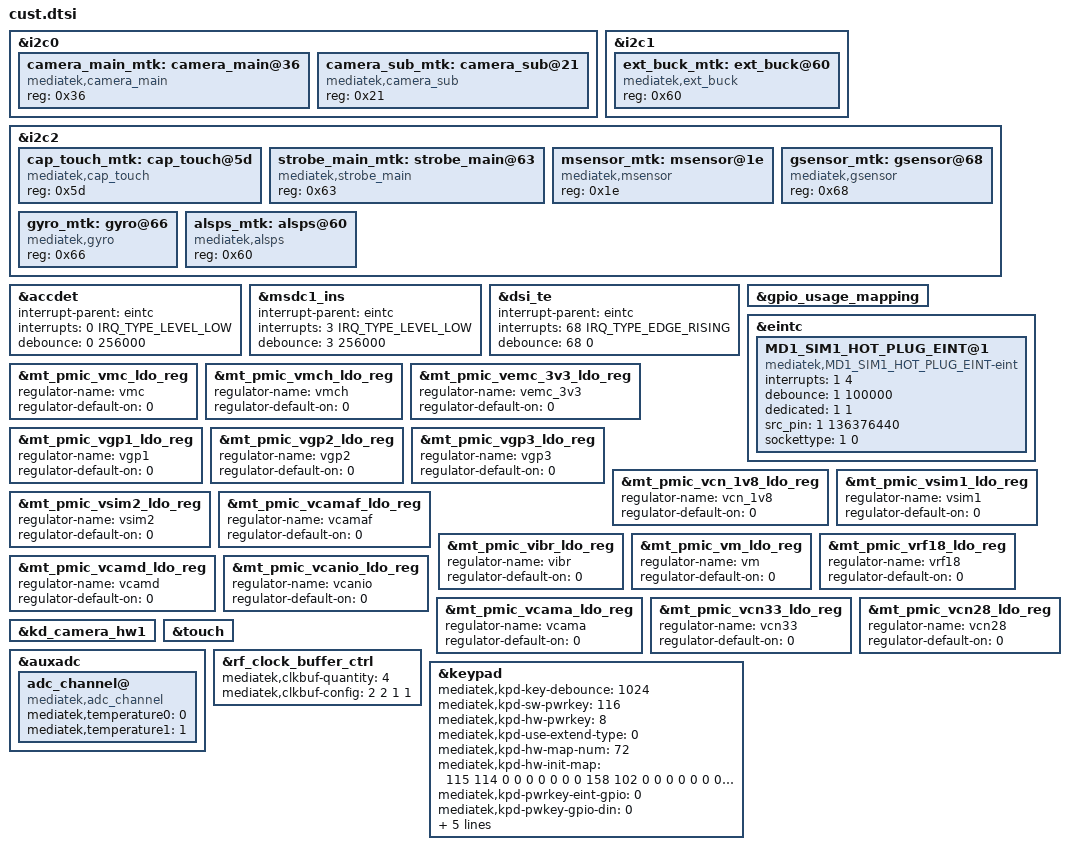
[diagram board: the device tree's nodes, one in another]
/*
 * Generated by MTK SP Drv_CodeGen Version 03.13.6  for MT6580. Copyright MediaTek Inc. (C) 2013.
 * Wed Sep 23 15:43:50 2020
 * Do Not Modify the File.
 */

/*************************
 * I2C DTSI File
*************************/

&i2c0 {
	#address-cells = <1>;
	#size-cells = <0>;
	camera_main_mtk:camera_main@36 {
		compatible = "mediatek,camera_main";
		reg = <0x36>;
		status = "okay";
	};
	camera_sub_mtk:camera_sub@21 {
		compatible = "mediatek,camera_sub";
		reg = <0x21>;
		status = "okay";
	};
};

&i2c1 {
	#address-cells = <1>;
	#size-cells = <0>;
	ext_buck_mtk:ext_buck@60 {
		compatible = "mediatek,ext_buck";
		reg = <0x60>;
		status = "okay";
	};
};

&i2c2 {
	#address-cells = <1>;
	#size-cells = <0>;
	cap_touch_mtk:cap_touch@5d {
		compatible = "mediatek,cap_touch";
		reg = <0x5d>;
		status = "okay";
	};
	strobe_main_mtk:strobe_main@63 {
		compatible = "mediatek,strobe_main";
		reg = <0x63>;
		status = "okay";
	};
	msensor_mtk:msensor@1e {
		compatible = "mediatek,msensor";
		reg = <0x1e>;
		status = "okay";
	};
	gsensor_mtk:gsensor@68 {
		compatible = "mediatek,gsensor";
		reg = <0x68>;
		status = "okay";
	};
	gyro_mtk:gyro@66 {
		compatible = "mediatek,gyro";
		reg = <0x66>;
		status = "okay";
	};
	alsps_mtk:alsps@60 {
		compatible = "mediatek,alsps";
		reg = <0x60>;
		status = "okay";
	};
};



#include <dt-bindings/interrupt-controller/irq.h>
#include <dt-bindings/interrupt-controller/arm-gic.h>

/*************************
 * EINT DTSI File
*************************/

&accdet {
	interrupt-parent = <&eintc>;
	interrupts = <0 IRQ_TYPE_LEVEL_LOW>;
	debounce = <0 256000>;
	status = "okay";
};
&msdc1_ins {
	interrupt-parent = <&eintc>;
	interrupts = <3 IRQ_TYPE_LEVEL_LOW>;
	debounce = <3 256000>;
	status = "okay";
};
&dsi_te {
	interrupt-parent = <&eintc>;
	interrupts = <68 IRQ_TYPE_EDGE_RISING>;
	debounce = <68 0>;
	status = "okay";
};


/********************
 * GPIO USAGE MAPPING DTSI File
****************/

&gpio_usage_mapping {
};


&eintc {
	MD1_SIM1_HOT_PLUG_EINT@1 {
		compatible = "mediatek,MD1_SIM1_HOT_PLUG_EINT-eint";
		interrupts = <1 4>;
		debounce = <1 100000>;
		dedicated = <1 1>;
		src_pin = <1 136376440>;
		sockettype=<1 0>;
		status = "okay";
	};
};


/*************************
 * PMIC DTSI File
*************************/

&mt_pmic_vmc_ldo_reg {
	regulator-name = "vmc";
	regulator-default-on = <0>; /* 0:skip, 1: off, 2:on */
	status = "okay";
};
&mt_pmic_vmch_ldo_reg {
	regulator-name = "vmch";
	regulator-default-on = <0>; /* 0:skip, 1: off, 2:on */
	status = "okay";
};
&mt_pmic_vemc_3v3_ldo_reg {
	regulator-name = "vemc_3v3";
	regulator-default-on = <0>; /* 0:skip, 1: off, 2:on */
	status = "okay";
};
&mt_pmic_vgp1_ldo_reg {
	regulator-name = "vgp1";
	regulator-default-on = <0>; /* 0:skip, 1: off, 2:on */
	status = "okay";
};
&mt_pmic_vgp2_ldo_reg {
	regulator-name = "vgp2";
	regulator-default-on = <0>; /* 0:skip, 1: off, 2:on */
	status = "okay";
};
&mt_pmic_vgp3_ldo_reg {
	regulator-name = "vgp3";
	regulator-default-on = <0>; /* 0:skip, 1: off, 2:on */
	status = "okay";
};
&mt_pmic_vcn_1v8_ldo_reg {
	regulator-name = "vcn_1v8";
	regulator-default-on = <0>; /* 0:skip, 1: off, 2:on */
	status = "okay";
};
&mt_pmic_vsim1_ldo_reg {
	regulator-name = "vsim1";
	regulator-default-on = <0>; /* 0:skip, 1: off, 2:on */
	status = "okay";
};
&mt_pmic_vsim2_ldo_reg {
	regulator-name = "vsim2";
	regulator-default-on = <0>; /* 0:skip, 1: off, 2:on */
	status = "okay";
};
&mt_pmic_vcamaf_ldo_reg {
	regulator-name = "vcamaf";
	regulator-default-on = <0>; /* 0:skip, 1: off, 2:on */
	status = "okay";
};
&mt_pmic_vibr_ldo_reg {
	regulator-name = "vibr";
	regulator-default-on = <0>; /* 0:skip, 1: off, 2:on */
	status = "okay";
};
&mt_pmic_vm_ldo_reg {
	regulator-name = "vm";
	regulator-default-on = <0>; /* 0:skip, 1: off, 2:on */
	status = "okay";
};
&mt_pmic_vrf18_ldo_reg {
	regulator-name = "vrf18";
	regulator-default-on = <0>; /* 0:skip, 1: off, 2:on */
	status = "okay";
};
&mt_pmic_vcamd_ldo_reg {
	regulator-name = "vcamd";
	regulator-default-on = <0>; /* 0:skip, 1: off, 2:on */
	status = "okay";
};
&mt_pmic_vcanio_ldo_reg {
	regulator-name = "vcanio";
	regulator-default-on = <0>; /* 0:skip, 1: off, 2:on */
	status = "okay";
};
&mt_pmic_vcama_ldo_reg {
	regulator-name = "vcama";
	regulator-default-on = <0>; /* 0:skip, 1: off, 2:on */
	status = "okay";
};
&mt_pmic_vcn33_ldo_reg {
	regulator-name = "vcn33";
	regulator-default-on = <0>; /* 0:skip, 1: off, 2:on */
	status = "okay";
};
&mt_pmic_vcn28_ldo_reg {
	regulator-name = "vcn28";
	regulator-default-on = <0>; /* 0:skip, 1: off, 2:on */
	status = "okay";
};

&kd_camera_hw1 {
	status = "okay";
};

&touch {
	status = "okay";
};


/********************************************
 *ADC DTSI File
********************************************/

&auxadc {
	adc_channel@ {
		compatible = "mediatek,adc_channel";
		mediatek,temperature0 = <0>;
		mediatek,temperature1 = <1>;
		status = "okay";
	};
};


/**********************************************
 *CLK_BUF DTSI File
********************************************/

&rf_clock_buffer_ctrl {
	mediatek,clkbuf-quantity = <4>;
	mediatek,clkbuf-config = <2 2 1 1>;
	status = "okay";
};


/**********************************************
 *Keypad DTSI File
********************************************/

&keypad{
	mediatek,kpd-key-debounce = <1024>;
	mediatek,kpd-sw-pwrkey = <116>;
	mediatek,kpd-hw-pwrkey = <8>;
	mediatek,kpd-use-extend-type = <0>;
	/*HW Keycode [0~71] -> Linux Keycode*/
	mediatek,kpd-hw-map-num = <72>;
	mediatek,kpd-hw-init-map = <115 114 0 0 0 0 0 0 0 158 
				102 0 0 0 0 0 0 0 0 
				0 0 0 0 0 0 0 0 0 
				0 0 0 0 0 0 0 0 0 
				0 0 0 0 0 0 0 0 0 
				0 0 0 0 0 0 0 0 0 
				0 0 0 0 0 0 0 0 0 
				0 0 0 0 0 0 0 0 >;
	mediatek,kpd-pwrkey-eint-gpio = <0>;
	mediatek,kpd-pwkey-gpio-din  = <0>;
	mediatek,kpd-hw-dl-key0 = <0>;
	mediatek,kpd-hw-dl-key1 = <1>;
	mediatek,kpd-hw-dl-key2 = <8>;
	mediatek,kpd-hw-recovery-key = <0>;
	mediatek,kpd-hw-factory-key = <1>;
	status = "okay";
};


